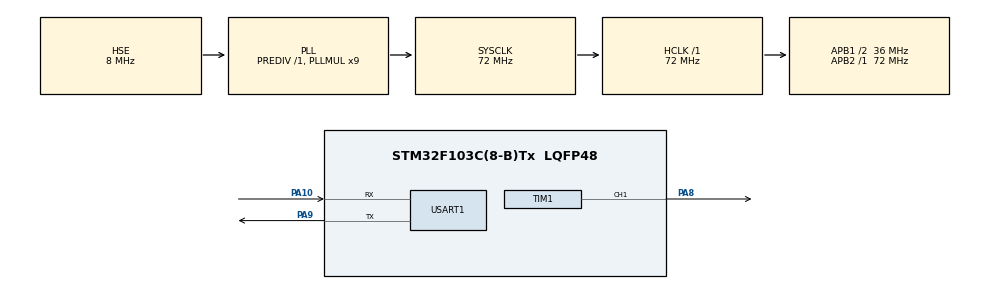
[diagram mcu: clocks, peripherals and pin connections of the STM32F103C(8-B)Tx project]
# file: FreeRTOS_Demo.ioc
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FREERTOS.Tasks01=pwmTask,24,256,StartPwmTask,Default,NULL,Dynamic,NULL,NULL;uartTask,8,256,StartUartTask,Default,NULL,Dynamic,NULL,NULL
FREERTOS.configTOTAL_HEAP_SIZE=8192
Mcu.Family=STM32F1
Mcu.Name=STM32F103C(8-B)Tx
Mcu.Package=LQFP48
NVIC.PriorityGroup=NVIC_PRIORITYGROUP_4
NVIC.TIM2_IRQn=true\:15\:0\:false\:false\:true\:false\:false\:true\:true
NVIC.TimeBase=TIM2_IRQn
NVIC.TimeBaseIP=TIM2
PA10.Mode=Asynchronous
PA10.Signal=USART1_RX
PA13.Mode=Serial_Wire
PA13.Signal=SYS_JTMS-SWDIO
PA14.Mode=Serial_Wire
PA14.Signal=SYS_JTCK-SWCLK
PA8.Signal=S_TIM1_CH1
PA9.Mode=Asynchronous
PA9.Signal=USART1_TX
PD0-OSC_IN.Mode=HSE-External-Oscillator
PD0-OSC_IN.Signal=RCC_OSC_IN
PD1-OSC_OUT.Mode=HSE-External-Oscillator
PD1-OSC_OUT.Signal=RCC_OSC_OUT
ProjectManager.HeapSize=0x200
ProjectManager.StackSize=0x400
ProjectManager.TargetToolchain=MDK-ARM V5.32
RCC.AHBFreq_Value=72000000
RCC.APB1CLKDivider=RCC_HCLK_DIV2
RCC.APB1Freq_Value=36000000
RCC.APB1TimFreq_Value=72000000
RCC.APB2Freq_Value=72000000
RCC.APB2TimFreq_Value=72000000
RCC.HCLKFreq_Value=72000000
RCC.PLLMUL=RCC_PLL_MUL9
RCC.PLLSourceVirtual=RCC_PLLSOURCE_HSE
RCC.SYSCLKFreq_VALUE=72000000
RCC.SYSCLKSource=RCC_SYSCLKSOURCE_PLLCLK
RCC.USBFreq_Value=72000000
SH.S_TIM1_CH1.0=TIM1_CH1,PWM Generation1 CH1
TIM1.Channel-PWM\ Generation1\ CH1=TIM_CHANNEL_1
TIM1.Period=999
TIM1.Prescaler=71
TIM1.Pulse-PWM\ Generation1\ CH1=500
USART1.VirtualMode=VM_ASYNC
VP_FREERTOS_VS_CMSIS_V2.Mode=CMSIS_V2
VP_SYS_VS_tim2.Mode=TIM2
VP_TIM1_VS_ClockSourceINT.Mode=Internal
board=custom

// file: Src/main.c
/* USER CODE BEGIN Header */
/**
  ******************************************************************************
  * @file           : main.c
  * @brief          : Main program body
  ******************************************************************************
  * @attention
  *
  * Copyright (c) 2026 STMicroelectronics.
  * All rights reserved.
  *
  * This software is licensed under terms that can be found in the LICENSE file
  * in the root directory of this software component.
  * If no LICENSE file comes with this software, it is provided AS-IS.
  *
  ******************************************************************************
  */
/* USER CODE END Header */
#include "main.h"
#include "cmsis_os.h"
#include "tim.h"
#include "usart.h"
#include "gpio.h"

void SystemClock_Config(void);
void MX_FREERTOS_Init(void);

int main(void)
{

  /* MCU Configuration--------------------------------------------------------*/

  /* Reset of all peripherals, Initializes the Flash interface and the Systick. */
  HAL_Init();

  /* Configure the system clock */
  SystemClock_Config();

  /* Initialize all configured peripherals */
  MX_GPIO_Init();
  MX_TIM1_Init();
  MX_USART1_UART_Init();

  /* Init scheduler */
  osKernelInitialize();  /* Call init function for freertos objects (in cmsis_os2.c) */
  MX_FREERTOS_Init();

  /* Start scheduler */
  osKernelStart();

  /* We should never get here as control is now taken by the scheduler */

  /* Infinite loop */
  while (1)
  {

  }
}

void SystemClock_Config(void)
{
  RCC_OscInitTypeDef RCC_OscInitStruct = {0};
  RCC_ClkInitTypeDef RCC_ClkInitStruct = {0};

  /** Initializes the RCC Oscillators according to the specified parameters
  * in the RCC_OscInitTypeDef structure.
  */
  RCC_OscInitStruct.OscillatorType = RCC_OSCILLATORTYPE_HSE;
  RCC_OscInitStruct.HSEState = RCC_HSE_ON;
  RCC_OscInitStruct.HSEPredivValue = RCC_HSE_PREDIV_DIV1;
  RCC_OscInitStruct.HSIState = RCC_HSI_ON;
  RCC_OscInitStruct.PLL.PLLState = RCC_PLL_ON;
  RCC_OscInitStruct.PLL.PLLSource = RCC_PLLSOURCE_HSE;
  RCC_OscInitStruct.PLL.PLLMUL = RCC_PLL_MUL9;
  if (HAL_RCC_OscConfig(&RCC_OscInitStruct) != HAL_OK)
  {
    Error_Handler();
  }

  /** Initializes the CPU, AHB and APB buses clocks
  */
  RCC_ClkInitStruct.ClockType = RCC_CLOCKTYPE_HCLK|RCC_CLOCKTYPE_SYSCLK
                              |RCC_CLOCKTYPE_PCLK1|RCC_CLOCKTYPE_PCLK2;
  RCC_ClkInitStruct.SYSCLKSource = RCC_SYSCLKSOURCE_PLLCLK;
  RCC_ClkInitStruct.AHBCLKDivider = RCC_SYSCLK_DIV1;
  RCC_ClkInitStruct.APB1CLKDivider = RCC_HCLK_DIV2;
  RCC_ClkInitStruct.APB2CLKDivider = RCC_HCLK_DIV1;

  if (HAL_RCC_ClockConfig(&RCC_ClkInitStruct, FLASH_LATENCY_2) != HAL_OK)
  {
    Error_Handler();
  }
}

void HAL_TIM_PeriodElapsedCallback(TIM_HandleTypeDef *htim)
{
  if (htim->Instance == TIM2)
  {
    HAL_IncTick();
  }
}

void Error_Handler(void)
{
  __disable_irq();
  while (1)
  {
  }
}

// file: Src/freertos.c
/* USER CODE BEGIN Header */
/**
  ******************************************************************************
  * File Name          : freertos.c
  * Description        : Code for freertos applications
  ******************************************************************************
  * @attention
  *
  * Copyright (c) 2026 STMicroelectronics.
  * All rights reserved.
  *
  * This software is licensed under terms that can be found in the LICENSE file
  * in the root directory of this software component.
  * If no LICENSE file comes with this software, it is provided AS-IS.
  *
  ******************************************************************************
  */
/* USER CODE END Header */

#include "FreeRTOS.h"
#include "task.h"
#include "main.h"
#include "cmsis_os.h"

/* USER CODE BEGIN Includes */
#include "breath_led.h"
#include "uart_echo.h"
/* USER CODE END Includes */

/* Definitions for pwmTask */
osThreadId_t pwmTaskHandle;
const osThreadAttr_t pwmTask_attributes = {
  .name = "pwmTask",
  .stack_size = 256 * 4,
  .priority = (osPriority_t) osPriorityNormal,
};
/* Definitions for uartTask */
osThreadId_t uartTaskHandle;
const osThreadAttr_t uartTask_attributes = {
  .name = "uartTask",
  .stack_size = 256 * 4,
  .priority = (osPriority_t) osPriorityLow,
};

void StartPwmTask(void *argument);
void StartUartTask(void *argument);

void MX_FREERTOS_Init(void); /* (MISRA C 2004 rule 8.1) */

void MX_FREERTOS_Init(void) {

  /* Create the thread(s) */
  /* creation of pwmTask */
  pwmTaskHandle = osThreadNew(StartPwmTask, NULL, &pwmTask_attributes);

  /* creation of uartTask */
  uartTaskHandle = osThreadNew(StartUartTask, NULL, &uartTask_attributes);

}

void StartPwmTask(void *argument)
{
  /* USER CODE BEGIN StartPwmTask */
  /* CubeMX 任务入口只负责转交，便于重新生成代码和查找业务模块。 */
  BreathLed_Task(argument);
/* USER CODE END StartPwmTask */
}

void StartUartTask(void *argument)
{
  /* USER CODE BEGIN StartUartTask */
  UartEcho_Task(argument);
/* USER CODE END StartUartTask */
}
